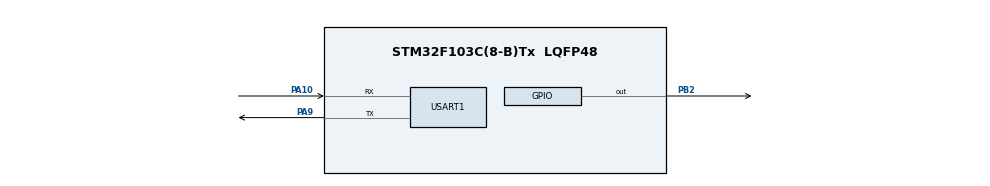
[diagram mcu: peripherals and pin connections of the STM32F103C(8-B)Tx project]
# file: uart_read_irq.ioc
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Mcu.Family=STM32F1
Mcu.Name=STM32F103C(8-B)Tx
Mcu.Package=LQFP48
NVIC.PriorityGroup=NVIC_PRIORITYGROUP_4
NVIC.USART1_IRQn=true\:1\:0\:true\:false\:true\:true\:true\:true
PA10.Mode=Asynchronous
PA10.Signal=USART1_RX
PA13.Mode=Serial_Wire
PA13.Signal=SYS_JTMS-SWDIO
PA14.Mode=Serial_Wire
PA14.Signal=SYS_JTCK-SWCLK
PA9.Mode=Asynchronous
PA9.Signal=USART1_TX
PB2.Signal=GPIO_Output
ProjectManager.HeapSize=0x3000
ProjectManager.StackSize=0x1000
ProjectManager.TargetToolchain=STM32CubeIDE
RCC.APB1Freq_Value=8000000
RCC.APB2Freq_Value=8000000
USART1.VirtualMode=VM_ASYNC
board=custom

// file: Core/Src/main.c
/* USER CODE BEGIN Header */
/**
 * Прием данных
Для организации передачи данных можно использовать прерывание
 «Receive data register not empty (data ready to be read)». Оно
вызывается каждый раз, когда на UART поступают данные. Для его
использования необходимо добавить/обновить код в трех файлах main.h, main.c, stm32f1xx_it.c

Прием данных по прерываниям в приведенной программе сводится к следующими шагам:
1. В основной программе на этапе инициализации:
	1) подготовка буфера:
	memset((void*) input_buf->buf, 0, INPUT_BUF_SIZE);
	input_buf->pos = 0;
	input_buf->huart = huart;

2) включение «receive data register not empty» прерывания:
	// enable interrupt
    __HAL_UART_ENABLE_IT(&huart2, UART_IT_RXNE);
	2. В основной программе (вечный цикл):
	чтение буфера принятых байт и его обработка:
	buf);
	// read input buffer content
	size = input_buf_read_content(&project_input_buf,
	// prepare content for “echo”
	strcpy(output_buf, “input buf: \””);
	offset = strlen(output_buf);
	for (int i = 0; i < size; i++) {
		sym = buf[i];
		// replace non printable symbols except spaces with dash
		if (!(sym == ‘ ‘ || isgraph(sym))) {
			sym = ‘-’;
		}
		output_buf[offset + i] = sym;
	}
	offset += size;
	strcpy(output_buf + offset, “\”\n”);
	// show echo
	HAL_UART_Transmit(&huart2, (uint8_t*) output_buf, strlen(output_buf), HAL_MAX_DELAY);

3. В обработчике прерывания (функции USART2_IRQHandler, input_buf_process_rxne_it):
	1) проверка того, что произошло прерывание «receive data register
	not empty». Это необходимо сделать, так как обработчик прерываний USART2_IRQHandler
	обслуживает все события, связанные с USART2:
	// ignore interrupt if it isn’t related with received
	data
	if (!__HAL_UART_GET_FLAG(input_buf->huart, UART_FLAG_RXNE)) {
		return 0;
	}
2) считывание байта из регистра UART и сохранение его в буфере:
	// read received data
	char sym = input_buf->huart->Instance->DR;
	// save symbol into buffer
	size_t pos = input_buf->pos;
	input_buf->buf[pos] = sym;
	pos++;
	if (pos >= INPUT_BUF_SIZE) {
		pos = 0;
	}
	input_buf->pos = pos;
 */
/**
  ******************************************************************************
  * @file           : main.c
  * @brief          : Main program body
  ******************************************************************************
  * @attention
  *
  * Copyright (c) 2025 STMicroelectronics.
  * All rights reserved.
  *
  * This software is licensed under terms that can be found in the LICENSE file
  * in the root directory of this software component.
  * If no LICENSE file comes with this software, it is provided AS-IS.
  *
  ******************************************************************************
  */
/* USER CODE END Header */
#include "main.h"

/* USER CODE BEGIN Includes */
#include <stdio.h>
#include <string.h>
#include <ctype.h>
/* USER CODE END Includes */

UART_HandleTypeDef huart1;

/* USER CODE BEGIN PV */
#ifndef __GNUC__
#error Unknown compilator
#else
#include <unistd.h>

int _write(int fd, const void *buf, size_t count)
{
	int res = 0;
	if (fd == STDOUT_FILENO || fd == STDERR_FILENO) {
		// write data to UART
		HAL_StatusTypeDef hal_res = HAL_UART_Transmit(&huart1, (uint8_t*) buf, count, HAL_MAX_DELAY);
		res = hal_res == HAL_OK ? count : -1;
	} else {
		res = -1;
	}
	return res;
}
#endif
/* USER CODE END PV */

void SystemClock_Config(void);
static void MX_GPIO_Init(void);
static void MX_USART1_UART_Init(void);

/* USER CODE BEGIN 0 */
// define global variable
input_buf_t project_input_buf;
/**
* Initialize input_line_buf_t object.
*/
int input_buf_init(input_buf_t *input_buf, UART_HandleTypeDef *huart)
{
	memset((void*) input_buf->buf, 0, INPUT_BUF_SIZE);
	input_buf->pos = 0;
	input_buf->huart = huart;
	// enable interrupt
	__HAL_UART_ENABLE_IT(&huart1, UART_IT_RXNE);
	return 0;
}
/**
* Read current content of the buffer.
*/
int input_buf_read_content(input_buf_t *input_buf, char *output)
{
	int pos = input_buf->pos;
	// copy data to `output` buffer
	for (int i = 0; i < INPUT_BUF_SIZE; i++) {
		output[i] = input_buf->buf[pos];
		pos++;
		if (pos >= INPUT_BUF_SIZE) {
			pos = 0;
		}
	}
	return INPUT_BUF_SIZE;
}

/**
* Process UART interruption.
*/
int input_buf_process_rxne_it(input_buf_t *input_buf)
{
	//printf("\ninput_buf->pos: %d\n", input_buf->pos);
// ignore interrupt if it isn't related with received data
	if (!__HAL_UART_GET_FLAG(input_buf->huart, UART_FLAG_RXNE)) {
		return 0;
	}
	// process received data
	char sym = input_buf->huart->Instance->DR;
	// save symbol into buffer
	size_t pos = input_buf->pos;
	input_buf->buf[pos] = sym;
	pos++;
	if (pos >= INPUT_BUF_SIZE) {
		pos = 0;
	}
	input_buf->pos = pos;
	return 0;
}
/* USER CODE END 0 */

int main(void)
{

  /* MCU Configuration--------------------------------------------------------*/

  /* Reset of all peripherals, Initializes the Flash interface and the Systick. */
  HAL_Init();

  /* Configure the system clock */
  SystemClock_Config();

  /* Initialize all configured peripherals */
  MX_GPIO_Init();
  MX_USART1_UART_Init();
  /* USER CODE BEGIN 2 */
  input_buf_init(&project_input_buf, &huart1);
  char buf[INPUT_BUF_SIZE + 1];
  char output_buf[INPUT_BUF_SIZE + 32];
  int size;
  int offset;
  char sym;
  /* USER CODE END 2 */

  /* Infinite loop */
  /* USER CODE BEGIN WHILE */
  while (1)
  {
	  // read input buffer content
	  size = input_buf_read_content(&project_input_buf, buf);
	  // prepare content for "echo"
	  strcpy(output_buf, "input buf: \"");
	  offset = strlen(output_buf);
	  for (int i = 0; i < size; i++) {
		  sym = buf[i];
		  // replace non printable symbols except spaces with dash
		  if (!(sym == ' ' || isgraph(sym))) {
			  sym = '-';
		  }
		  output_buf[offset + i] = sym;
	  }
	  offset += size;
	  strcpy(output_buf + offset, "\"\n");
	  // show echo
	  HAL_UART_Transmit(&huart1, (uint8_t*) output_buf,  strlen(output_buf), HAL_MAX_DELAY);
	  HAL_GPIO_TogglePin(GPIOB, GPIO_PIN_2);
	  HAL_Delay(1000);
    /* USER CODE END WHILE */

  }
}

void SystemClock_Config(void)
{
  RCC_OscInitTypeDef RCC_OscInitStruct = {0};
  RCC_ClkInitTypeDef RCC_ClkInitStruct = {0};

  /** Initializes the RCC Oscillators according to the specified parameters
  * in the RCC_OscInitTypeDef structure.
  */
  RCC_OscInitStruct.OscillatorType = RCC_OSCILLATORTYPE_HSI;
  RCC_OscInitStruct.HSIState = RCC_HSI_ON;
  RCC_OscInitStruct.HSICalibrationValue = RCC_HSICALIBRATION_DEFAULT;
  RCC_OscInitStruct.PLL.PLLState = RCC_PLL_NONE;
  if (HAL_RCC_OscConfig(&RCC_OscInitStruct) != HAL_OK)
  {
    Error_Handler();
  }

  /** Initializes the CPU, AHB and APB buses clocks
  */
  RCC_ClkInitStruct.ClockType = RCC_CLOCKTYPE_HCLK|RCC_CLOCKTYPE_SYSCLK
                              |RCC_CLOCKTYPE_PCLK1|RCC_CLOCKTYPE_PCLK2;
  RCC_ClkInitStruct.SYSCLKSource = RCC_SYSCLKSOURCE_HSI;
  RCC_ClkInitStruct.AHBCLKDivider = RCC_SYSCLK_DIV1;
  RCC_ClkInitStruct.APB1CLKDivider = RCC_HCLK_DIV1;
  RCC_ClkInitStruct.APB2CLKDivider = RCC_HCLK_DIV1;

  if (HAL_RCC_ClockConfig(&RCC_ClkInitStruct, FLASH_LATENCY_0) != HAL_OK)
  {
    Error_Handler();
  }
}

static void MX_USART1_UART_Init(void)
{

  huart1.Instance = USART1;
  huart1.Init.BaudRate = 115200;
  huart1.Init.WordLength = UART_WORDLENGTH_8B;
  huart1.Init.StopBits = UART_STOPBITS_1;
  huart1.Init.Parity = UART_PARITY_NONE;
  huart1.Init.Mode = UART_MODE_TX_RX;
  huart1.Init.HwFlowCtl = UART_HWCONTROL_NONE;
  huart1.Init.OverSampling = UART_OVERSAMPLING_16;
  if (HAL_UART_Init(&huart1) != HAL_OK)
  {
    Error_Handler();
  }

}

static void MX_GPIO_Init(void)
{
  GPIO_InitTypeDef GPIO_InitStruct = {0};

  /* GPIO Ports Clock Enable */
  __HAL_RCC_GPIOB_CLK_ENABLE();
  __HAL_RCC_GPIOA_CLK_ENABLE();

  /*Configure GPIO pin Output Level */
  HAL_GPIO_WritePin(GPIOB, GPIO_PIN_2, GPIO_PIN_RESET);

  /*Configure GPIO pin : PB2 */
  GPIO_InitStruct.Pin = GPIO_PIN_2;
  GPIO_InitStruct.Mode = GPIO_MODE_OUTPUT_PP;
  GPIO_InitStruct.Pull = GPIO_NOPULL;
  GPIO_InitStruct.Speed = GPIO_SPEED_FREQ_LOW;
  HAL_GPIO_Init(GPIOB, &GPIO_InitStruct);

}

void Error_Handler(void)
{
  __disable_irq();
  while (1)
  {
  }
}
